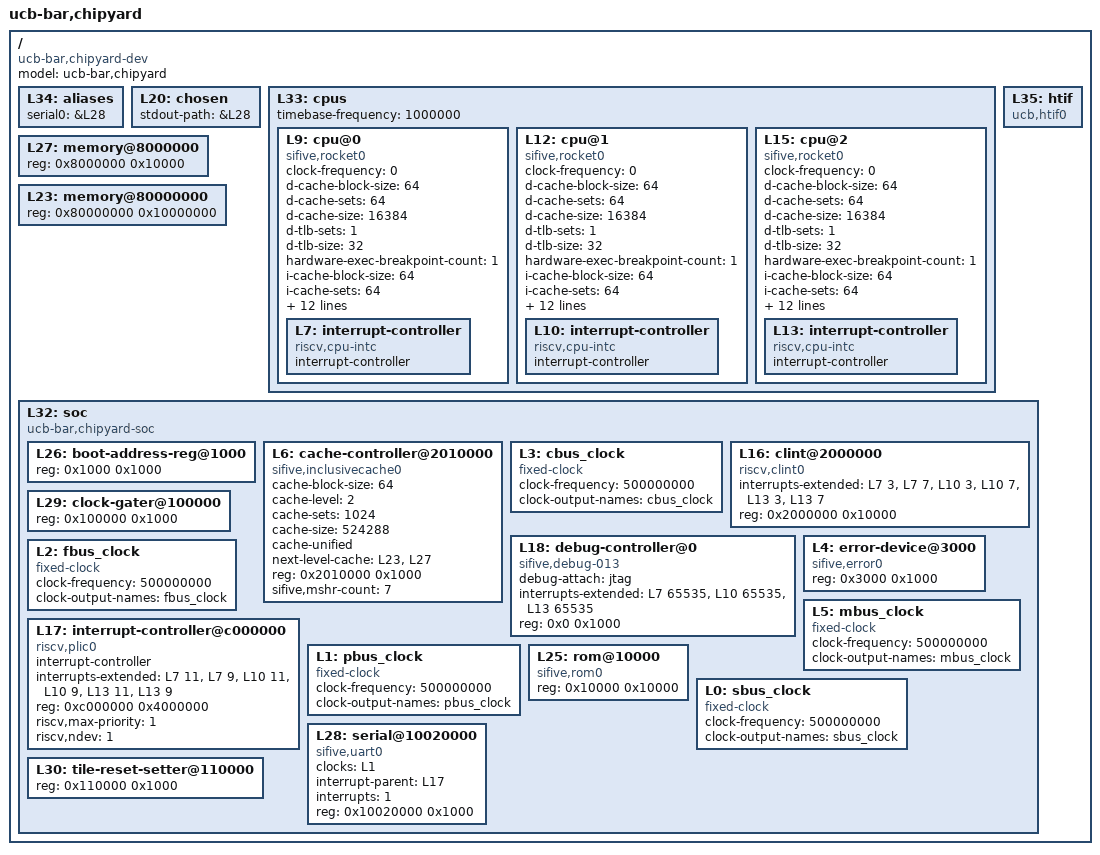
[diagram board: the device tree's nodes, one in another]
/dts-v1/;

/ {
	#address-cells = <1>;
	#size-cells = <1>;
	compatible = "ucb-bar,chipyard-dev";
	model = "ucb-bar,chipyard";
	L34: aliases {
		serial0 = &L28;
	};
	L20: chosen {
		stdout-path = &L28;
	};
	L33: cpus {
		#address-cells = <1>;
		#size-cells = <0>;
		timebase-frequency = <1000000>;
		L9: cpu@0 {
			clock-frequency = <0>;
			compatible = "sifive,rocket0", "riscv";
			d-cache-block-size = <64>;
			d-cache-sets = <64>;
			d-cache-size = <16384>;
			d-tlb-sets = <1>;
			d-tlb-size = <32>;
			device_type = "cpu";
			hardware-exec-breakpoint-count = <1>;
			i-cache-block-size = <64>;
			i-cache-sets = <64>;
			i-cache-size = <16384>;
			i-tlb-sets = <1>;
			i-tlb-size = <32>;
			mmu-type = "riscv,sv39";
			next-level-cache = <&L6>;
			reg = <0x0>;
			riscv,isa = "rv64imafdczicsr_zifencei_zihpm_xrocket";
			riscv,pmpgranularity = <4>;
			riscv,pmpregions = <8>;
			status = "okay";
			timebase-frequency = <1000000>;
			tlb-split;
			L7: interrupt-controller {
				#interrupt-cells = <1>;
				compatible = "riscv,cpu-intc";
				interrupt-controller;
			};
		};
		L12: cpu@1 {
			clock-frequency = <0>;
			compatible = "sifive,rocket0", "riscv";
			d-cache-block-size = <64>;
			d-cache-sets = <64>;
			d-cache-size = <16384>;
			d-tlb-sets = <1>;
			d-tlb-size = <32>;
			device_type = "cpu";
			hardware-exec-breakpoint-count = <1>;
			i-cache-block-size = <64>;
			i-cache-sets = <64>;
			i-cache-size = <16384>;
			i-tlb-sets = <1>;
			i-tlb-size = <32>;
			mmu-type = "riscv,sv39";
			next-level-cache = <&L6>;
			reg = <0x1>;
			riscv,isa = "rv64imafdczicsr_zifencei_zihpm_xrocket";
			riscv,pmpgranularity = <4>;
			riscv,pmpregions = <8>;
			status = "okay";
			timebase-frequency = <1000000>;
			tlb-split;
			L10: interrupt-controller {
				#interrupt-cells = <1>;
				compatible = "riscv,cpu-intc";
				interrupt-controller;
			};
		};
		L15: cpu@2 {
			clock-frequency = <0>;
			compatible = "sifive,rocket0", "riscv";
			d-cache-block-size = <64>;
			d-cache-sets = <64>;
			d-cache-size = <16384>;
			d-tlb-sets = <1>;
			d-tlb-size = <32>;
			device_type = "cpu";
			hardware-exec-breakpoint-count = <1>;
			i-cache-block-size = <64>;
			i-cache-sets = <64>;
			i-cache-size = <16384>;
			i-tlb-sets = <1>;
			i-tlb-size = <32>;
			mmu-type = "riscv,sv39";
			next-level-cache = <&L6>;
			reg = <0x2>;
			riscv,isa = "rv64imafdczicsr_zifencei_zihpm_xrocket";
			riscv,pmpgranularity = <4>;
			riscv,pmpregions = <8>;
			status = "okay";
			timebase-frequency = <1000000>;
			tlb-split;
			L13: interrupt-controller {
				#interrupt-cells = <1>;
				compatible = "riscv,cpu-intc";
				interrupt-controller;
			};
		};
	};
	L35: htif {
		compatible = "ucb,htif0";
	};
	L27: memory@8000000 {
		device_type = "memory";
		reg = <0x8000000 0x10000>;
	};
	L23: memory@80000000 {
		device_type = "memory";
		reg = <0x80000000 0x10000000>;
	};
	L32: soc {
		#address-cells = <1>;
		#size-cells = <1>;
		compatible = "ucb-bar,chipyard-soc", "simple-bus";
		ranges;
		L26: boot-address-reg@1000 {
			reg = <0x1000 0x1000>;
			reg-names = "control";
		};
		L6: cache-controller@2010000 {
			cache-block-size = <64>;
			cache-level = <2>;
			cache-sets = <1024>;
			cache-size = <524288>;
			cache-unified;
			compatible = "sifive,inclusivecache0", "cache";
			next-level-cache = <&L23 &L27>;
			reg = <0x2010000 0x1000>;
			reg-names = "control";
			sifive,mshr-count = <7>;
		};
		L3: cbus_clock {
			#clock-cells = <0>;
			clock-frequency = <500000000>;
			clock-output-names = "cbus_clock";
			compatible = "fixed-clock";
		};
		L16: clint@2000000 {
			compatible = "riscv,clint0";
			interrupts-extended = <&L7 3 &L7 7 &L10 3 &L10 7 &L13 3 &L13 7>;
			reg = <0x2000000 0x10000>;
			reg-names = "control";
		};
		L29: clock-gater@100000 {
			reg = <0x100000 0x1000>;
			reg-names = "control";
		};
		L18: debug-controller@0 {
			compatible = "sifive,debug-013", "riscv,debug-013";
			debug-attach = "jtag";
			interrupts-extended = <&L7 65535 &L10 65535 &L13 65535>;
			reg = <0x0 0x1000>;
			reg-names = "control";
		};
		L4: error-device@3000 {
			compatible = "sifive,error0";
			reg = <0x3000 0x1000>;
		};
		L2: fbus_clock {
			#clock-cells = <0>;
			clock-frequency = <500000000>;
			clock-output-names = "fbus_clock";
			compatible = "fixed-clock";
		};
		L17: interrupt-controller@c000000 {
			#interrupt-cells = <1>;
			compatible = "riscv,plic0";
			interrupt-controller;
			interrupts-extended = <&L7 11 &L7 9 &L10 11 &L10 9 &L13 11 &L13 9>;
			reg = <0xc000000 0x4000000>;
			reg-names = "control";
			riscv,max-priority = <1>;
			riscv,ndev = <1>;
		};
		L5: mbus_clock {
			#clock-cells = <0>;
			clock-frequency = <500000000>;
			clock-output-names = "mbus_clock";
			compatible = "fixed-clock";
		};
		L1: pbus_clock {
			#clock-cells = <0>;
			clock-frequency = <500000000>;
			clock-output-names = "pbus_clock";
			compatible = "fixed-clock";
		};
		L25: rom@10000 {
			compatible = "sifive,rom0";
			reg = <0x10000 0x10000>;
			reg-names = "mem";
		};
		L0: sbus_clock {
			#clock-cells = <0>;
			clock-frequency = <500000000>;
			clock-output-names = "sbus_clock";
			compatible = "fixed-clock";
		};
		L28: serial@10020000 {
			clocks = <&L1>;
			compatible = "sifive,uart0";
			interrupt-parent = <&L17>;
			interrupts = <1>;
			reg = <0x10020000 0x1000>;
			reg-names = "control";
		};
		L30: tile-reset-setter@110000 {
			reg = <0x110000 0x1000>;
			reg-names = "control";
		};
	};
};
